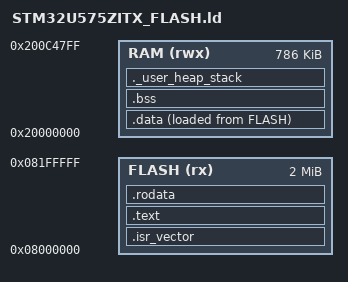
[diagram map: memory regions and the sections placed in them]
/*
 * Linker script — STM32U575ZITx (2 MB Flash, 786 KB SRAM)
 */
MEMORY
{
    FLASH  (rx)  : ORIGIN = 0x08000000, LENGTH = 2048K
    RAM    (rwx) : ORIGIN = 0x20000000, LENGTH = 786K
}

_estack = ORIGIN(RAM) + LENGTH(RAM);

SECTIONS
{
    .isr_vector :
    {
        . = ALIGN(4);
        KEEP(*(.isr_vector))
        . = ALIGN(4);
    } > FLASH

    .text :
    {
        . = ALIGN(4);
        *(.text)
        *(.text*)
        *(.glue_7)
        *(.glue_7t)
        KEEP(*(.init))
        KEEP(*(.fini))
        . = ALIGN(4);
        _etext = .;
    } > FLASH

    .rodata :
    {
        . = ALIGN(4);
        *(.rodata)
        *(.rodata*)
        . = ALIGN(4);
    } > FLASH

    _sidata = LOADADDR(.data);

    .data :
    {
        . = ALIGN(4);
        _sdata = .;
        *(.data)
        *(.data*)
        . = ALIGN(4);
        _edata = .;
    } > RAM AT> FLASH

    .bss :
    {
        . = ALIGN(4);
        _sbss = .;
        *(.bss)
        *(.bss*)
        *(COMMON)
        . = ALIGN(4);
        _ebss = .;
    } > RAM

    ._user_heap_stack :
    {
        . = ALIGN(8);
        PROVIDE(end = .);
        PROVIDE(_end = .);
        . = . + 0x400;
        . = . + 0x800;
        . = ALIGN(8);
    } > RAM
}
